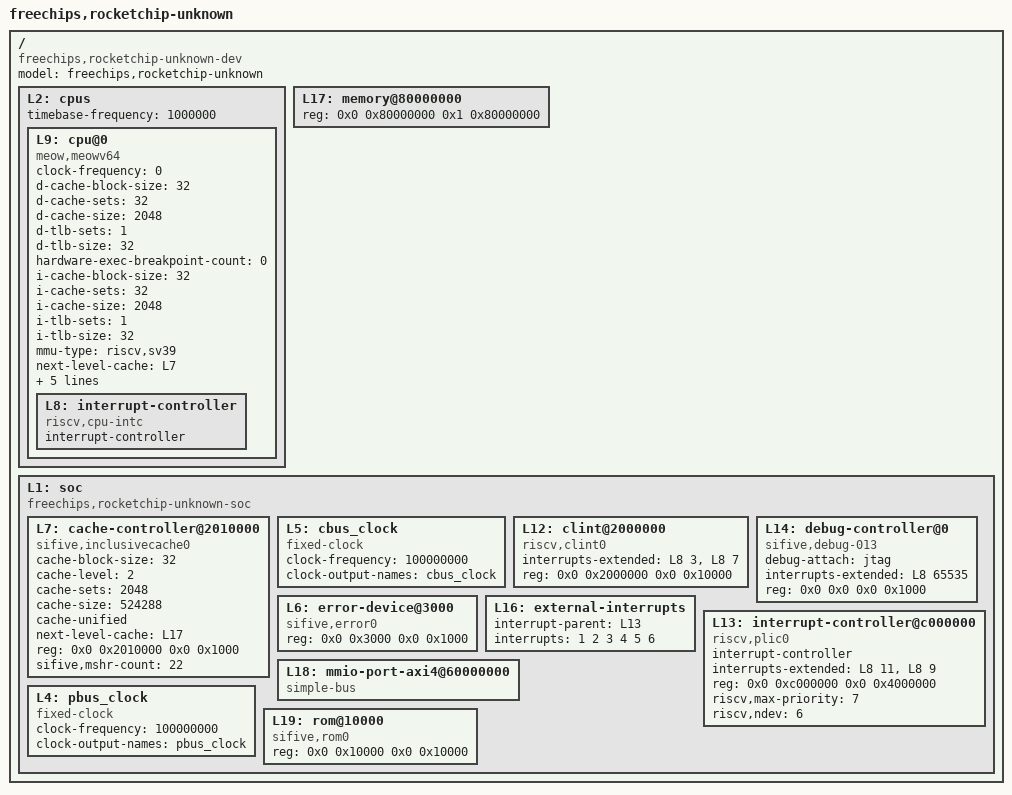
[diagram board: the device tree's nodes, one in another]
/dts-v1/;

/ {
	#address-cells = <2>;
	#size-cells = <2>;
	compatible = "freechips,rocketchip-unknown-dev";
	model = "freechips,rocketchip-unknown";
	L2: cpus {
		#address-cells = <1>;
		#size-cells = <0>;
		timebase-frequency = <1000000>;
		L9: cpu@0 {
			clock-frequency = <0>;
			compatible = "meow,meowv64", "riscv";
			d-cache-block-size = <32>;
			d-cache-sets = <32>;
			d-cache-size = <2048>;
			d-tlb-sets = <1>;
			d-tlb-size = <32>;
			device_type = "cpu";
			hardware-exec-breakpoint-count = <0>;
			i-cache-block-size = <32>;
			i-cache-sets = <32>;
			i-cache-size = <2048>;
			i-tlb-sets = <1>;
			i-tlb-size = <32>;
			mmu-type = "riscv,sv39";
			next-level-cache = <&L7>;
			reg = <0x0>;
			riscv,isa = "rv64imafdczicsr_zifencei_zihpm_zvl256b_zve64x";
			status = "okay";
			timebase-frequency = <1000000>;
			tlb-split;
			L8: interrupt-controller {
				#interrupt-cells = <1>;
				compatible = "riscv,cpu-intc";
				interrupt-controller;
			};
		};
	};
	L17: memory@80000000 {
		device_type = "memory";
		reg = <0x0 0x80000000 0x1 0x80000000>;
	};
	L1: soc {
		#address-cells = <2>;
		#size-cells = <2>;
		compatible = "freechips,rocketchip-unknown-soc", "simple-bus";
		ranges;
		L7: cache-controller@2010000 {
			cache-block-size = <32>;
			cache-level = <2>;
			cache-sets = <2048>;
			cache-size = <524288>;
			cache-unified;
			compatible = "sifive,inclusivecache0", "cache";
			next-level-cache = <&L17>;
			reg = <0x0 0x2010000 0x0 0x1000>;
			reg-names = "control";
			sifive,mshr-count = <22>;
		};
		L5: cbus_clock {
			#clock-cells = <0>;
			clock-frequency = <100000000>;
			clock-output-names = "cbus_clock";
			compatible = "fixed-clock";
		};
		L12: clint@2000000 {
			compatible = "riscv,clint0";
			interrupts-extended = <&L8 3 &L8 7>;
			reg = <0x0 0x2000000 0x0 0x10000>;
			reg-names = "control";
		};
		L14: debug-controller@0 {
			compatible = "sifive,debug-013", "riscv,debug-013";
			debug-attach = "jtag";
			interrupts-extended = <&L8 65535>;
			reg = <0x0 0x0 0x0 0x1000>;
			reg-names = "control";
		};
		L6: error-device@3000 {
			compatible = "sifive,error0";
			reg = <0x0 0x3000 0x0 0x1000>;
		};
		L16: external-interrupts {
			interrupt-parent = <&L13>;
			interrupts = <1 2 3 4 5 6>;
		};
		L13: interrupt-controller@c000000 {
			#interrupt-cells = <1>;
			compatible = "riscv,plic0";
			interrupt-controller;
			interrupts-extended = <&L8 11 &L8 9>;
			reg = <0x0 0xc000000 0x0 0x4000000>;
			reg-names = "control";
			riscv,max-priority = <7>;
			riscv,ndev = <6>;
		};
		L18: mmio-port-axi4@60000000 {
			#address-cells = <2>;
			#size-cells = <1>;
			compatible = "simple-bus";
			ranges = <0x0 0x60000000 0x0 0x60000000 0x20000000 0x2 0x0 0x2 0x0 0x0>;
		};
		L4: pbus_clock {
			#clock-cells = <0>;
			clock-frequency = <100000000>;
			clock-output-names = "pbus_clock";
			compatible = "fixed-clock";
		};
		L19: rom@10000 {
			compatible = "sifive,rom0";
			reg = <0x0 0x10000 0x0 0x10000>;
			reg-names = "mem";
		};
	};
};
